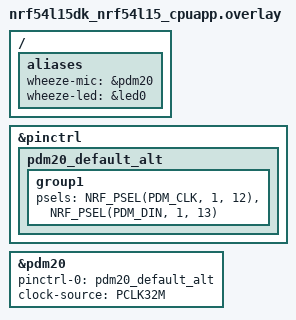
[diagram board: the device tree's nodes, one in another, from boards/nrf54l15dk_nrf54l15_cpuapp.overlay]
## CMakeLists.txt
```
cmake_minimum_required(VERSION 3.20.0)

# Pull in the wheeze module. In your own project either do the same with the
# path to wheeze/, or add the module to your west.yml (see README).
list(APPEND ZEPHYR_EXTRA_MODULES ${CMAKE_CURRENT_SOURCE_DIR}/../wheeze)

find_package(Zephyr REQUIRED HINTS $ENV{ZEPHYR_BASE})
project(wheeze_app LANGUAGES C CXX)

target_sources(app PRIVATE src/main.c)
```

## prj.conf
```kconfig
# Battery build (default). For logs/profiling add:  -DEXTRA_CONF_FILE=debug.conf

# The detector (selects PDM/DMIC, FPU, CMSIS-DSP, CMSIS-NN, full libstdc++)
CONFIG_WHEEZE_DETECTOR=y
CONFIG_CPP=y
CONFIG_STD_CPP20=y

# ---- power ----
# A running UART (console/logging) draws more than the entire detector, and
# keeps the high-frequency clock requested. Compile all of it out.
CONFIG_SERIAL=n
CONFIG_CONSOLE=n
CONFIG_UART_CONSOLE=n
CONFIG_LOG=n
CONFIG_PRINTK=n
CONFIG_BOOT_BANNER=n
# Let drivers suspend peripherals that are not in use
CONFIG_PM_DEVICE=y
```

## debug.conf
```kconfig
# Bring-up / profiling overlay:  west build ... -- -DEXTRA_CONF_FILE=debug.conf
# Enables UART logging and the detector's DWT profiling. Not for battery measurements.
CONFIG_SERIAL=y
CONFIG_CONSOLE=y
CONFIG_UART_CONSOLE=y
CONFIG_LOG=y
CONFIG_PRINTK=y
CONFIG_BOOT_BANNER=y
CONFIG_WHEEZE_PROFILING=y
```

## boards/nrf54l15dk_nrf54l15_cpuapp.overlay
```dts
/*
 * PDM MEMS mic on the nRF54L15 DK.
 * PDM20 lives in the PERI power domain, so CLK/DIN must be port 1 pins.
 * P1.12 = PDM CLK, P1.13 = PDM DATA (same as Zephyr's dmic sample).
 * Mic SEL/LR pin -> GND (left channel), VDD 1.8 V, CLK/DATA direct.
 */
/ {
	aliases {
		wheeze-mic = &pdm20;
		wheeze-led = &led0; /* optional: remove to never drive an LED */
	};
};

&pinctrl {
	pdm20_default_alt: pdm20_default_alt {
		group1 {
			psels = <NRF_PSEL(PDM_CLK, 1, 12)>,
				<NRF_PSEL(PDM_DIN, 1, 13)>;
		};
	};
};

&pdm20 {
	status = "okay";
	pinctrl-0 = <&pdm20_default_alt>;
	pinctrl-names = "default";
	clock-source = "PCLK32M";
};
```

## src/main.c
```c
/*
 * Minimal integration of the wheeze detector: start it, react to events.
 * Replace the callback body with your own output (BLE notify, store, ...).
 */
#include <zephyr/kernel.h>
#include <zephyr/logging/log.h>
#include <wheeze/wheeze.h>

LOG_MODULE_REGISTER(app, LOG_LEVEL_INF);

static void on_wheeze(const struct wheeze_event *evt, void *user_data)
{
	ARG_UNUSED(user_data);

	if (evt->type == WHEEZE_EVT_END) {
		LOG_INF("wheeze #%u: %u ms (p=%d%%)", evt->count, evt->duration_ms,
			(int)(evt->probability * 100));
	}
}

int main(void)
{
	int err = wheeze_start(on_wheeze, NULL);

	if (err) {
		LOG_ERR("wheeze_start failed: %d", err);
	}
	return 0; /* the detector keeps running in its own thread */
}
```
